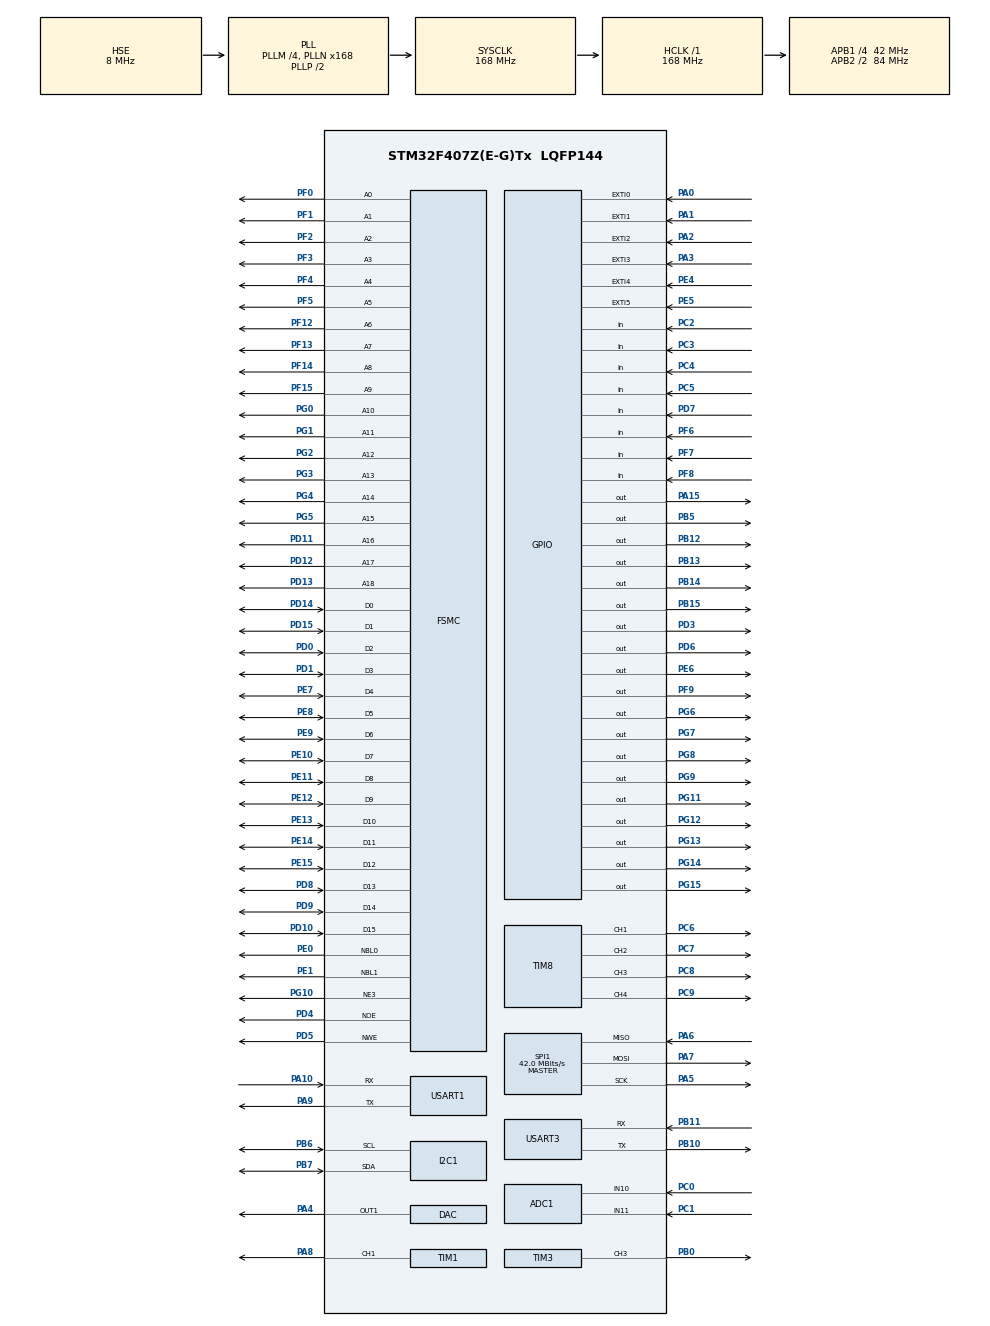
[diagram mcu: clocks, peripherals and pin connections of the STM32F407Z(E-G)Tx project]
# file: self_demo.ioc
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ADC1.Channel-0\#ChannelRegularConversion=ADC_CHANNEL_10
ADC1.ClockPrescaler=ADC_CLOCK_SYNC_PCLK_DIV4
ADC1.ContinuousConvMode=DISABLE
ADC1.DiscontinuousConvMode=DISABLE
ADC1.NbrOfConversion=1
ADC1.NbrOfConversionFlag=1
ADC1.Rank-0\#ChannelRegularConversion=1
ADC1.SamplingTime-0\#ChannelRegularConversion=ADC_SAMPLETIME_144CYCLES
ADC1.ScanConvMode=DISABLE
ADC1.master=1
Dma.DAC1.4.Direction=DMA_MEMORY_TO_PERIPH
Dma.DAC1.4.FIFOMode=DMA_FIFOMODE_DISABLE
Dma.DAC1.4.Instance=DMA1_Stream5
Dma.DAC1.4.MemDataAlignment=DMA_MDATAALIGN_HALFWORD
Dma.DAC1.4.MemInc=DMA_MINC_ENABLE
Dma.DAC1.4.Mode=DMA_CIRCULAR
Dma.DAC1.4.PeriphDataAlignment=DMA_PDATAALIGN_HALFWORD
Dma.DAC1.4.PeriphInc=DMA_PINC_DISABLE
Dma.DAC1.4.Priority=DMA_PRIORITY_LOW
Dma.I2C1_RX.2.Direction=DMA_PERIPH_TO_MEMORY
Dma.I2C1_RX.2.FIFOMode=DMA_FIFOMODE_DISABLE
Dma.I2C1_RX.2.Instance=DMA1_Stream0
Dma.I2C1_RX.2.MemDataAlignment=DMA_MDATAALIGN_BYTE
Dma.I2C1_RX.2.MemInc=DMA_MINC_ENABLE
Dma.I2C1_RX.2.Mode=DMA_NORMAL
Dma.I2C1_RX.2.PeriphDataAlignment=DMA_PDATAALIGN_BYTE
Dma.I2C1_RX.2.PeriphInc=DMA_PINC_DISABLE
Dma.I2C1_RX.2.Priority=DMA_PRIORITY_LOW
Dma.I2C1_TX.3.Direction=DMA_MEMORY_TO_PERIPH
Dma.I2C1_TX.3.FIFOMode=DMA_FIFOMODE_DISABLE
Dma.I2C1_TX.3.Instance=DMA1_Stream6
Dma.I2C1_TX.3.MemDataAlignment=DMA_MDATAALIGN_BYTE
Dma.I2C1_TX.3.MemInc=DMA_MINC_ENABLE
Dma.I2C1_TX.3.Mode=DMA_NORMAL
Dma.I2C1_TX.3.PeriphDataAlignment=DMA_PDATAALIGN_BYTE
Dma.I2C1_TX.3.PeriphInc=DMA_PINC_DISABLE
Dma.I2C1_TX.3.Priority=DMA_PRIORITY_LOW
Dma.Request0=SPI1_RX
Dma.Request1=SPI1_TX
Dma.Request2=I2C1_RX
Dma.Request3=I2C1_TX
Dma.Request4=DAC1
Dma.SPI1_RX.0.Direction=DMA_PERIPH_TO_MEMORY
Dma.SPI1_RX.0.FIFOMode=DMA_FIFOMODE_DISABLE
Dma.SPI1_RX.0.Instance=DMA2_Stream0
Dma.SPI1_RX.0.MemDataAlignment=DMA_MDATAALIGN_BYTE
Dma.SPI1_RX.0.MemInc=DMA_MINC_ENABLE
Dma.SPI1_RX.0.Mode=DMA_NORMAL
Dma.SPI1_RX.0.PeriphDataAlignment=DMA_PDATAALIGN_BYTE
Dma.SPI1_RX.0.PeriphInc=DMA_PINC_DISABLE
Dma.SPI1_RX.0.Priority=DMA_PRIORITY_MEDIUM
Dma.SPI1_TX.1.Direction=DMA_MEMORY_TO_PERIPH
Dma.SPI1_TX.1.FIFOMode=DMA_FIFOMODE_DISABLE
Dma.SPI1_TX.1.Instance=DMA2_Stream3
Dma.SPI1_TX.1.MemDataAlignment=DMA_MDATAALIGN_BYTE
Dma.SPI1_TX.1.MemInc=DMA_MINC_ENABLE
Dma.SPI1_TX.1.Mode=DMA_NORMAL
Dma.SPI1_TX.1.PeriphDataAlignment=DMA_PDATAALIGN_BYTE
Dma.SPI1_TX.1.PeriphInc=DMA_PINC_DISABLE
Dma.SPI1_TX.1.Priority=DMA_PRIORITY_MEDIUM
FSMC.WriteOperation1=FSMC_WRITE_OPERATION_ENABLE
Mcu.Family=STM32F4
Mcu.Name=STM32F407Z(E-G)Tx
Mcu.Package=LQFP144
NVIC.DMA1_Stream0_IRQn=true\:5\:0\:true\:false\:true\:false\:true\:true
NVIC.DMA1_Stream5_IRQn=true\:0\:0\:false\:false\:true\:false\:true\:true
NVIC.DMA1_Stream6_IRQn=true\:5\:0\:true\:false\:true\:false\:true\:true
NVIC.DMA2_Stream0_IRQn=true\:5\:0\:true\:false\:true\:false\:true\:true
NVIC.DMA2_Stream3_IRQn=true\:5\:0\:true\:false\:true\:false\:true\:true
NVIC.EXTI0_IRQn=true\:3\:0\:true\:false\:true\:true\:true\:true
NVIC.EXTI1_IRQn=true\:3\:0\:true\:false\:true\:true\:true\:true
NVIC.EXTI2_IRQn=true\:3\:0\:true\:false\:true\:true\:true\:true
NVIC.EXTI3_IRQn=true\:3\:0\:true\:false\:true\:true\:true\:true
NVIC.EXTI4_IRQn=true\:3\:0\:true\:false\:true\:true\:true\:true
NVIC.EXTI9_5_IRQn=true\:3\:0\:true\:false\:true\:true\:true\:true
NVIC.I2C1_EV_IRQn=true\:1\:0\:true\:false\:true\:true\:true\:true
NVIC.PriorityGroup=NVIC_PRIORITYGROUP_4
NVIC.SPI1_IRQn=true\:4\:0\:true\:false\:true\:true\:true\:true
NVIC.TIM1_UP_TIM10_IRQn=true\:3\:0\:true\:false\:true\:true\:true\:true
NVIC.TIM2_IRQn=true\:2\:0\:true\:false\:true\:true\:true\:true
NVIC.TIM6_DAC_IRQn=true\:1\:0\:true\:false\:true\:true\:true\:true
NVIC.TIM7_IRQn=true\:1\:0\:true\:false\:true\:true\:true\:true
NVIC.TIM8_UP_TIM13_IRQn=true\:0\:0\:false\:false\:true\:true\:true\:true
NVIC.USART1_IRQn=true\:4\:0\:true\:false\:true\:true\:true\:true
NVIC.USART3_IRQn=true\:0\:0\:false\:false\:true\:true\:true\:true
PA0-WKUP.Signal=GPXTI0
PA1.Signal=GPXTI1
PA10.Mode=Asynchronous
PA10.Signal=USART1_RX
PA13.Mode=Serial_Wire
PA13.Signal=SYS_JTMS-SWDIO
PA14.Mode=Serial_Wire
PA14.Signal=SYS_JTCK-SWCLK
PA15.GPIO_ModeDefaultOutputPP=GPIO_MODE_OUTPUT_OD
PA15.GPIO_PuPd=GPIO_NOPULL
PA15.PinState=GPIO_PIN_SET
PA15.Signal=GPIO_Output
PA2.Signal=GPXTI2
PA3.Signal=GPXTI3
PA4.Signal=COMP_DAC1_group
PA5.Mode=Full_Duplex_Master
PA5.Signal=SPI1_SCK
PA6.Mode=Full_Duplex_Master
PA6.Signal=SPI1_MISO
PA7.Mode=Full_Duplex_Master
PA7.Signal=SPI1_MOSI
PA8.Signal=S_TIM1_CH1
PA9.Mode=Asynchronous
PA9.Signal=USART1_TX
PB0.Signal=S_TIM3_CH3
PB10.Mode=Asynchronous
PB10.Signal=USART3_TX
PB11.Mode=Asynchronous
PB11.Signal=USART3_RX
PB12.GPIO_ModeDefaultOutputPP=GPIO_MODE_OUTPUT_OD
PB12.GPIO_PuPd=GPIO_NOPULL
PB12.PinState=GPIO_PIN_SET
PB12.Signal=GPIO_Output
PB13.GPIO_ModeDefaultOutputPP=GPIO_MODE_OUTPUT_OD
PB13.GPIO_PuPd=GPIO_NOPULL
PB13.PinState=GPIO_PIN_SET
PB13.Signal=GPIO_Output
PB14.GPIO_ModeDefaultOutputPP=GPIO_MODE_OUTPUT_OD
PB14.GPIO_PuPd=GPIO_NOPULL
PB14.PinState=GPIO_PIN_SET
PB14.Signal=GPIO_Output
PB15.GPIO_ModeDefaultOutputPP=GPIO_MODE_OUTPUT_OD
PB15.GPIO_PuPd=GPIO_NOPULL
PB15.GPIO_Speed=GPIO_SPEED_FREQ_LOW
PB15.PinState=GPIO_PIN_SET
PB15.Signal=GPIO_Output
PB5.GPIO_ModeDefaultOutputPP=GPIO_MODE_OUTPUT_OD
PB5.GPIO_PuPd=GPIO_NOPULL
PB5.GPIO_Speed=GPIO_SPEED_FREQ_LOW
PB5.PinState=GPIO_PIN_SET
PB5.Signal=GPIO_Output
PB6.Mode=I2C
PB6.Signal=I2C1_SCL
PB7.Mode=I2C
PB7.Signal=I2C1_SDA
PC0.Signal=ADCx_IN10
PC1.Signal=ADCx_IN11
PC14-OSC32_IN.Mode=LSE-External-Oscillator
PC14-OSC32_IN.Signal=RCC_OSC32_IN
PC15-OSC32_OUT.Mode=LSE-External-Oscillator
PC15-OSC32_OUT.Signal=RCC_OSC32_OUT
PC2.Signal=GPIO_Input
PC3.Signal=GPIO_Input
PC4.Signal=GPIO_Input
PC5.Signal=GPIO_Input
PC6.Signal=S_TIM8_CH1
PC7.Signal=S_TIM8_CH2
PC8.Signal=S_TIM8_CH3
PC9.Signal=S_TIM8_CH4
PD0.Signal=FSMC_D2_DA2
PD1.Signal=FSMC_D3_DA3
PD10.Signal=FSMC_D15_DA15
PD11.Signal=FSMC_A16_CLE
PD12.Signal=FSMC_A17_ALE
PD13.Signal=FSMC_A18
PD14.Signal=FSMC_D0_DA0
PD15.Signal=FSMC_D1_DA1
PD3.GPIO_Speed=GPIO_SPEED_FREQ_LOW
PD3.PinState=GPIO_PIN_SET
PD3.Signal=GPIO_Output
PD4.Signal=FSMC_NOE
PD5.Signal=FSMC_NWE
PD6.Signal=GPIO_Output
PD7.GPIO_PuPd=GPIO_PULLDOWN
PD7.Signal=GPIO_Input
PD8.Signal=FSMC_D13_DA13
PD9.Signal=FSMC_D14_DA14
PE0.Signal=FSMC_NBL0
PE1.Signal=FSMC_NBL1
PE10.Signal=FSMC_D7_DA7
PE11.Signal=FSMC_D8_DA8
PE12.Signal=FSMC_D9_DA9
PE13.Signal=FSMC_D10_DA10
PE14.Signal=FSMC_D11_DA11
PE15.Signal=FSMC_D12_DA12
PE4.GPIO_ModeDefaultEXTI=GPIO_MODE_IT_RISING_FALLING
PE4.Signal=GPXTI4
PE5.GPIO_ModeDefaultEXTI=GPIO_MODE_IT_RISING_FALLING
PE5.Signal=GPXTI5
PE6.PinState=GPIO_PIN_SET
PE6.Signal=GPIO_Output
PE7.Signal=FSMC_D4_DA4
PE8.Signal=FSMC_D5_DA5
PE9.Signal=FSMC_D6_DA6
PF0.Signal=FSMC_A0
PF1.Signal=FSMC_A1
PF12.Signal=FSMC_A6
PF13.Signal=FSMC_A7
PF14.Signal=FSMC_A8
PF15.Signal=FSMC_A9
PF2.Signal=FSMC_A2
PF3.Signal=FSMC_A3
PF4.Signal=FSMC_A4
PF5.Signal=FSMC_A5
PF6.Signal=GPIO_Input
PF7.Signal=GPIO_Input
PF8.Signal=GPIO_Input
PF9.GPIO_Speed=GPIO_SPEED_FREQ_LOW
PF9.PinState=GPIO_PIN_RESET
PF9.Signal=GPIO_Output
PG0.Signal=FSMC_A10
PG1.Signal=FSMC_A11
PG10.Mode=NorPsramChipSelect3_1
PG10.Signal=FSMC_NE3
PG11.Signal=GPIO_Output
PG12.Signal=GPIO_Output
PG13.Signal=GPIO_Output
PG14.Signal=GPIO_Output
PG15.GPIO_ModeDefaultOutputPP=GPIO_MODE_OUTPUT_OD
PG15.GPIO_PuPd=GPIO_NOPULL
PG15.GPIO_Speed=GPIO_SPEED_FREQ_LOW
PG15.PinState=GPIO_PIN_SET
PG15.Signal=GPIO_Output
PG2.Signal=FSMC_A12
PG3.Signal=FSMC_A13
PG4.Signal=FSMC_A14
PG5.Signal=FSMC_A15
PG6.Signal=GPIO_Output
PG7.Signal=GPIO_Output
PG8.Signal=GPIO_Output
PG9.Signal=GPIO_Output
PH0-OSC_IN.Mode=HSE-External-Oscillator
PH0-OSC_IN.Signal=RCC_OSC_IN
PH1-OSC_OUT.Mode=HSE-External-Oscillator
PH1-OSC_OUT.Signal=RCC_OSC_OUT
ProjectManager.HeapSize=0x200
ProjectManager.StackSize=0x400
ProjectManager.TargetToolchain=CMake
RCC.48MHZClocksFreq_Value=84000000
RCC.AHBFreq_Value=168000000
RCC.APB1CLKDivider=RCC_HCLK_DIV4
RCC.APB1Freq_Value=42000000
RCC.APB1TimFreq_Value=84000000
RCC.APB2CLKDivider=RCC_HCLK_DIV2
RCC.APB2Freq_Value=84000000
RCC.APB2TimFreq_Value=168000000
RCC.CortexFreq_Value=168000000
RCC.HCLKFreq_Value=168000000
RCC.HSE_VALUE=8000000
RCC.HSI_VALUE=16000000
RCC.PLLM=4
RCC.PLLN=168
RCC.PLLSourceVirtual=RCC_PLLSOURCE_HSE
RCC.RCC_RTC_Clock_Source=RCC_RTCCLKSOURCE_LSE
RCC.RCC_RTC_Clock_SourceVirtual=RCC_RTCCLKSOURCE_LSE
RCC.SYSCLKFreq_VALUE=168000000
RCC.SYSCLKSource=RCC_SYSCLKSOURCE_PLLCLK
RCC.VCOOutputFreq_Value=336000000
SH.ADCx_IN10.0=ADC1_IN10,IN10
SH.ADCx_IN11.0=ADC1_IN11,IN11
SH.COMP_DAC1_group.0=DAC_OUT1,DAC_OUT1
SH.FSMC_A0.0=FSMC_A0,19b-a1
SH.FSMC_A1.0=FSMC_A1,19b-a1
SH.FSMC_A10.0=FSMC_A10,19b-a1
SH.FSMC_A11.0=FSMC_A11,19b-a1
SH.FSMC_A12.0=FSMC_A12,19b-a1
SH.FSMC_A13.0=FSMC_A13,19b-a1
SH.FSMC_A14.0=FSMC_A14,19b-a1
SH.FSMC_A15.0=FSMC_A15,19b-a1
SH.FSMC_A16_CLE.0=FSMC_A16,19b-a1
SH.FSMC_A17_ALE.0=FSMC_A17,19b-a1
SH.FSMC_A18.0=FSMC_A18,19b-a1
SH.FSMC_A2.0=FSMC_A2,19b-a1
SH.FSMC_A3.0=FSMC_A3,19b-a1
SH.FSMC_A4.0=FSMC_A4,19b-a1
SH.FSMC_A5.0=FSMC_A5,19b-a1
SH.FSMC_A6.0=FSMC_A6,19b-a1
SH.FSMC_A7.0=FSMC_A7,19b-a1
SH.FSMC_A8.0=FSMC_A8,19b-a1
SH.FSMC_A9.0=FSMC_A9,19b-a1
SH.FSMC_D0_DA0.0=FSMC_D0,16b-d1
SH.FSMC_D10_DA10.0=FSMC_D10,16b-d1
SH.FSMC_D11_DA11.0=FSMC_D11,16b-d1
SH.FSMC_D12_DA12.0=FSMC_D12,16b-d1
SH.FSMC_D13_DA13.0=FSMC_D13,16b-d1
SH.FSMC_D14_DA14.0=FSMC_D14,16b-d1
SH.FSMC_D15_DA15.0=FSMC_D15,16b-d1
SH.FSMC_D1_DA1.0=FSMC_D1,16b-d1
SH.FSMC_D2_DA2.0=FSMC_D2,16b-d1
SH.FSMC_D3_DA3.0=FSMC_D3,16b-d1
SH.FSMC_D4_DA4.0=FSMC_D4,16b-d1
SH.FSMC_D5_DA5.0=FSMC_D5,16b-d1
SH.FSMC_D6_DA6.0=FSMC_D6,16b-d1
SH.FSMC_D7_DA7.0=FSMC_D7,16b-d1
SH.FSMC_D8_DA8.0=FSMC_D8,16b-d1
SH.FSMC_D9_DA9.0=FSMC_D9,16b-d1
SH.FSMC_NBL0.0=FSMC_NBL0,2ByteEnable1
SH.FSMC_NBL1.0=FSMC_NBL1,2ByteEnable1
SH.FSMC_NOE.0=FSMC_NOE,Sram1
SH.FSMC_NWE.0=FSMC_NWE,Sram1
SH.S_TIM1_CH1.0=TIM1_CH1,PWM Generation1 CH1
SH.S_TIM3_CH3.0=TIM3_CH3,PWM Generation3 CH3
SH.S_TIM8_CH1.0=TIM8_CH1,PWM Generation1 CH1
SH.S_TIM8_CH2.0=TIM8_CH2,PWM Generation2 CH2
SH.S_TIM8_CH3.0=TIM8_CH3,PWM Generation3 CH3
SH.S_TIM8_CH4.0=TIM8_CH4,PWM Generation4 CH4
SPI1.BaudRatePrescaler=SPI_BAUDRATEPRESCALER_2
SPI1.CalculateBaudRate=42.0 MBits/s
SPI1.DataSize=SPI_DATASIZE_8BIT
SPI1.Direction=SPI_DIRECTION_2LINES
SPI1.Mode=SPI_MODE_MASTER
SPI1.VirtualType=VM_MASTER
TIM1.Channel-PWM\ Generation1\ CH1=TIM_CHANNEL_1
TIM2.CounterMode=TIM_COUNTERMODE_UP
TIM3.Channel-PWM\ Generation3\ CH3=TIM_CHANNEL_3
TIM4.TIM_MasterOutputTrigger=TIM_TRGO_UPDATE
TIM8.Channel-PWM\ Generation1\ CH1=TIM_CHANNEL_1
TIM8.Channel-PWM\ Generation2\ CH2=TIM_CHANNEL_2
TIM8.Channel-PWM\ Generation3\ CH3=TIM_CHANNEL_3
TIM8.Channel-PWM\ Generation4\ CH4=TIM_CHANNEL_4
USART1.VirtualMode=VM_ASYNC
USART3.VirtualMode=VM_ASYNC
VP_RTC_VS_RTC_Activate.Mode=RTC_Enabled
VP_TIM10_VS_ClockSourceINT.Mode=Enable_Timer
VP_TIM11_VS_ClockSourceINT.Mode=Enable_Timer
VP_TIM13_VS_ClockSourceINT.Mode=Enable_Timer
VP_TIM1_VS_ClockSourceINT.Mode=Internal
VP_TIM2_VS_ClockSourceINT.Mode=Internal
VP_TIM4_VS_ClockSourceINT.Mode=Internal
VP_TIM6_VS_ClockSourceINT.Mode=Enable_Timer
VP_TIM7_VS_ClockSourceINT.Mode=Enable_Timer
VP_TIM8_VS_ClockSourceINT.Mode=Internal
board=custom

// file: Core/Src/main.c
/* USER CODE BEGIN Header */
/**
  ******************************************************************************
  * @file           : main.c
  * @brief          : Main program body
  ******************************************************************************
  * @attention
  *
  * Copyright (c) 2025 STMicroelectronics.
  * All rights reserved.
  *
  * This software is licensed under terms that can be found in the LICENSE file
  * in the root directory of this software component.
  * If no LICENSE file comes with this software, it is provided AS-IS.
  *
  ******************************************************************************
  */
/* USER CODE END Header */
#include "main.h"
#include "adc.h"
#include "dac.h"
#include "dma.h"
#include "i2c.h"
#include "rtc.h"
#include "spi.h"
#include "tim.h"
#include "usart.h"
#include "gpio.h"
#include "fsmc.h"

/* USER CODE BEGIN Includes */
#include "src/application/fmc/fmc.h"
#include <stdio.h>
/* USER CODE END Includes */

void SystemClock_Config(void);

int main(void)
{

  /* MCU Configuration--------------------------------------------------------*/

  /* Reset of all peripherals, Initializes the Flash interface and the Systick. */
  HAL_Init();

  /* Configure the system clock */
  SystemClock_Config();

  /* Initialize all configured peripherals */
  MX_GPIO_Init();
  MX_DMA_Init();
  MX_RTC_Init();
  MX_USART1_UART_Init();
  MX_SPI1_Init();
  MX_I2C1_Init();
  MX_TIM2_Init();
  MX_TIM8_Init();
  MX_TIM1_Init();
  MX_TIM3_Init();
  MX_TIM6_Init();
  MX_TIM7_Init();
  MX_TIM10_Init();
  MX_TIM11_Init();
  MX_USART3_UART_Init();
  MX_TIM13_Init();
  MX_ADC1_Init();
  MX_DAC_Init();
  MX_TIM4_Init();
  MX_FSMC_Init();
  /* USER CODE BEGIN 2 */
  fmc_test();
  /* USER CODE END 2 */

  /* Infinite loop */
  while (1)
  {

  }
}

void SystemClock_Config(void)
{
  RCC_OscInitTypeDef RCC_OscInitStruct = {0};
  RCC_ClkInitTypeDef RCC_ClkInitStruct = {0};

  /** Configure the main internal regulator output voltage
  */
  __HAL_RCC_PWR_CLK_ENABLE();
  __HAL_PWR_VOLTAGESCALING_CONFIG(PWR_REGULATOR_VOLTAGE_SCALE1);

  /** Initializes the RCC Oscillators according to the specified parameters
  * in the RCC_OscInitTypeDef structure.
  */
  RCC_OscInitStruct.OscillatorType = RCC_OSCILLATORTYPE_HSE|RCC_OSCILLATORTYPE_LSE;
  RCC_OscInitStruct.HSEState = RCC_HSE_ON;
  RCC_OscInitStruct.LSEState = RCC_LSE_ON;
  RCC_OscInitStruct.PLL.PLLState = RCC_PLL_ON;
  RCC_OscInitStruct.PLL.PLLSource = RCC_PLLSOURCE_HSE;
  RCC_OscInitStruct.PLL.PLLM = 4;
  RCC_OscInitStruct.PLL.PLLN = 168;
  RCC_OscInitStruct.PLL.PLLP = RCC_PLLP_DIV2;
  RCC_OscInitStruct.PLL.PLLQ = 4;
  if (HAL_RCC_OscConfig(&RCC_OscInitStruct) != HAL_OK)
  {
    Error_Handler();
  }

  /** Initializes the CPU, AHB and APB buses clocks
  */
  RCC_ClkInitStruct.ClockType = RCC_CLOCKTYPE_HCLK|RCC_CLOCKTYPE_SYSCLK
                              |RCC_CLOCKTYPE_PCLK1|RCC_CLOCKTYPE_PCLK2;
  RCC_ClkInitStruct.SYSCLKSource = RCC_SYSCLKSOURCE_PLLCLK;
  RCC_ClkInitStruct.AHBCLKDivider = RCC_SYSCLK_DIV1;
  RCC_ClkInitStruct.APB1CLKDivider = RCC_HCLK_DIV4;
  RCC_ClkInitStruct.APB2CLKDivider = RCC_HCLK_DIV2;

  if (HAL_RCC_ClockConfig(&RCC_ClkInitStruct, FLASH_LATENCY_5) != HAL_OK)
  {
    Error_Handler();
  }
}

void Error_Handler(void)
{
  __disable_irq();
  while (1)
  {
  }
}
